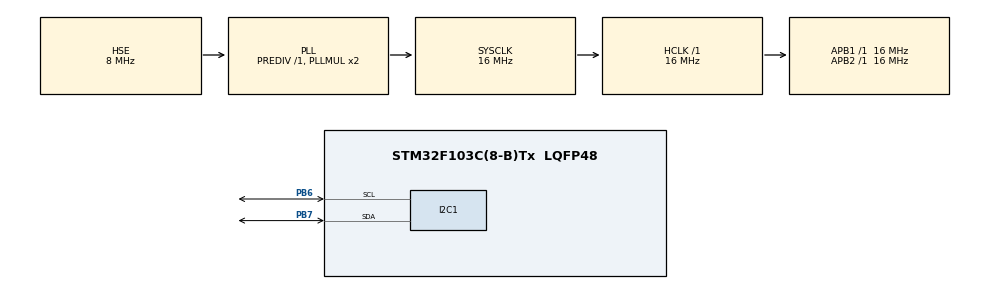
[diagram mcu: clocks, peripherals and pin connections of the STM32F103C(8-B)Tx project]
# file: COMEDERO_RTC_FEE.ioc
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Mcu.Family=STM32F1
Mcu.Name=STM32F103C(8-B)Tx
Mcu.Package=LQFP48
NVIC.PriorityGroup=NVIC_PRIORITYGROUP_4
PA13.Mode=Serial_Wire
PA13.Signal=SYS_JTMS-SWDIO
PA14.Mode=Serial_Wire
PA14.Signal=SYS_JTCK-SWCLK
PB6.Mode=I2C
PB6.Signal=I2C1_SCL
PB7.Mode=I2C
PB7.Signal=I2C1_SDA
PD0-OSC_IN.Mode=HSE-External-Oscillator
PD0-OSC_IN.Signal=RCC_OSC_IN
PD1-OSC_OUT.Mode=HSE-External-Oscillator
PD1-OSC_OUT.Signal=RCC_OSC_OUT
ProjectManager.HeapSize=0x200
ProjectManager.StackSize=0x400
ProjectManager.TargetToolchain=STM32CubeIDE
RCC.AHBFreq_Value=16000000
RCC.APB1Freq_Value=16000000
RCC.APB1TimFreq_Value=16000000
RCC.APB2Freq_Value=16000000
RCC.APB2TimFreq_Value=16000000
RCC.HCLKFreq_Value=16000000
RCC.PLLSourceVirtual=RCC_PLLSOURCE_HSE
RCC.SYSCLKFreq_VALUE=16000000
RCC.SYSCLKSource=RCC_SYSCLKSOURCE_PLLCLK
RCC.USBFreq_Value=16000000
RTC.Hours=16
RTC.Minutes=10
TIM2.Prescaler=15
VP_RTC_VS_RTC_Activate.Mode=RTC_Enabled
VP_RTC_VS_RTC_Calendar.Mode=RTC_Calendar
VP_TIM2_VS_ClockSourceINT.Mode=Internal
board=custom

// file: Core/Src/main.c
/* USER CODE BEGIN Header */
/**
  ******************************************************************************
  * @file           : main.c
  * @brief          : Main program body
  ******************************************************************************
  * @attention
  *
  * Copyright (c) 2025 STMicroelectronics.
  * All rights reserved.
  *
  * This software is licensed under terms that can be found in the LICENSE file
  * in the root directory of this software component.
  * If no LICENSE file comes with this software, it is provided AS-IS.
  *
  ******************************************************************************
  */
/* USER CODE END Header */
#include "main.h"

/* USER CODE BEGIN Includes */
#include "I2C_LCD.h"
#include "FEE.h"
/* USER CODE END Includes */

/* USER CODE BEGIN PD */

#define MyI2C_LCD I2C_LCD_1

/* USER CODE END PD */

I2C_HandleTypeDef hi2c1;

RTC_HandleTypeDef hrtc;

TIM_HandleTypeDef htim2;

/* USER CODE BEGIN PV */
RTC_TimeTypeDef gTime;
/* USER CODE END PV */

void SystemClock_Config(void);
static void MX_GPIO_Init(void);
static void MX_TIM2_Init(void);
static void MX_I2C1_Init(void);
static void MX_RTC_Init(void);

int main(void)
{

  /* USER CODE BEGIN 1 */

	uint16_t i = 0;
  /* USER CODE END 1 */

  /* MCU Configuration--------------------------------------------------------*/

  /* Reset of all peripherals, Initializes the Flash interface and the Systick. */
  HAL_Init();

  /* Configure the system clock */
  SystemClock_Config();

  /* Initialize all configured peripherals */
  MX_GPIO_Init();
  MX_TIM2_Init();
  MX_I2C1_Init();
  MX_RTC_Init();
  /* USER CODE BEGIN 2 */
  I2C_LCD_Init(MyI2C_LCD);
  I2C_LCD_SetCursor(MyI2C_LCD, 0, 0);
  I2C_LCD_WriteString(MyI2C_LCD, "Hora actual: ");
  I2C_LCD_SetCursor(MyI2C_LCD, 0, 1);

  FEE_ReadData(FEE_START_ADDRESS, &gTime, sizeof(RTC_TimeTypeDef));
  HAL_RTC_SetTime(&hrtc, &gTime, RTC_FORMAT_BIN);
  /* USER CODE END 2 */

  /* Infinite loop */
  /* USER CODE BEGIN WHILE */
  while (1)
  {
	  HAL_RTC_GetTime(&hrtc, &gTime, RTC_FORMAT_BIN);
	  I2C_LCD_WriteInt32(MyI2C_LCD, (int32_t)gTime.Hours);
	  I2C_LCD_WriteChar(MyI2C_LCD, ':');
	  I2C_LCD_WriteInt32(MyI2C_LCD, (int32_t)gTime.Minutes);
	  I2C_LCD_WriteChar(MyI2C_LCD, ':');
	  I2C_LCD_WriteInt32(MyI2C_LCD, (int32_t)gTime.Seconds);
	  I2C_LCD_SetCursor(MyI2C_LCD, 0, 1);
	  HAL_Delay(1000);
	  I2C_LCD_WriteString(MyI2C_LCD, "                ");
	  I2C_LCD_SetCursor(MyI2C_LCD, 0, 1);
    /* USER CODE END WHILE */

    /* USER CODE BEGIN 3 */
	  i++;
	  if(i == 300)
	  {
		  FEE_WriteData(FEE_START_ADDRESS, &gTime, sizeof(RTC_TimeTypeDef));
	  }
  }
  /* USER CODE END 3 */
}

void SystemClock_Config(void)
{
  RCC_OscInitTypeDef RCC_OscInitStruct = {0};
  RCC_ClkInitTypeDef RCC_ClkInitStruct = {0};
  RCC_PeriphCLKInitTypeDef PeriphClkInit = {0};

  /** Initializes the RCC Oscillators according to the specified parameters
  * in the RCC_OscInitTypeDef structure.
  */
  RCC_OscInitStruct.OscillatorType = RCC_OSCILLATORTYPE_LSI|RCC_OSCILLATORTYPE_HSE;
  RCC_OscInitStruct.HSEState = RCC_HSE_ON;
  RCC_OscInitStruct.HSEPredivValue = RCC_HSE_PREDIV_DIV1;
  RCC_OscInitStruct.HSIState = RCC_HSI_ON;
  RCC_OscInitStruct.LSIState = RCC_LSI_ON;
  RCC_OscInitStruct.PLL.PLLState = RCC_PLL_ON;
  RCC_OscInitStruct.PLL.PLLSource = RCC_PLLSOURCE_HSE;
  RCC_OscInitStruct.PLL.PLLMUL = RCC_PLL_MUL2;
  if (HAL_RCC_OscConfig(&RCC_OscInitStruct) != HAL_OK)
  {
    Error_Handler();
  }

  /** Initializes the CPU, AHB and APB buses clocks
  */
  RCC_ClkInitStruct.ClockType = RCC_CLOCKTYPE_HCLK|RCC_CLOCKTYPE_SYSCLK
                              |RCC_CLOCKTYPE_PCLK1|RCC_CLOCKTYPE_PCLK2;
  RCC_ClkInitStruct.SYSCLKSource = RCC_SYSCLKSOURCE_PLLCLK;
  RCC_ClkInitStruct.AHBCLKDivider = RCC_SYSCLK_DIV1;
  RCC_ClkInitStruct.APB1CLKDivider = RCC_HCLK_DIV1;
  RCC_ClkInitStruct.APB2CLKDivider = RCC_HCLK_DIV1;

  if (HAL_RCC_ClockConfig(&RCC_ClkInitStruct, FLASH_LATENCY_0) != HAL_OK)
  {
    Error_Handler();
  }
  PeriphClkInit.PeriphClockSelection = RCC_PERIPHCLK_RTC;
  PeriphClkInit.RTCClockSelection = RCC_RTCCLKSOURCE_LSI;
  if (HAL_RCCEx_PeriphCLKConfig(&PeriphClkInit) != HAL_OK)
  {
    Error_Handler();
  }
}

static void MX_I2C1_Init(void)
{

  hi2c1.Instance = I2C1;
  hi2c1.Init.ClockSpeed = 100000;
  hi2c1.Init.DutyCycle = I2C_DUTYCYCLE_2;
  hi2c1.Init.OwnAddress1 = 0;
  hi2c1.Init.AddressingMode = I2C_ADDRESSINGMODE_7BIT;
  hi2c1.Init.DualAddressMode = I2C_DUALADDRESS_DISABLE;
  hi2c1.Init.OwnAddress2 = 0;
  hi2c1.Init.GeneralCallMode = I2C_GENERALCALL_DISABLE;
  hi2c1.Init.NoStretchMode = I2C_NOSTRETCH_DISABLE;
  if (HAL_I2C_Init(&hi2c1) != HAL_OK)
  {
    Error_Handler();
  }

}

static void MX_RTC_Init(void)
{

  RTC_TimeTypeDef sTime = {0};
  RTC_DateTypeDef DateToUpdate = {0};

  /** Initialize RTC Only
  */
  hrtc.Instance = RTC;
  hrtc.Init.AsynchPrediv = RTC_AUTO_1_SECOND;
  hrtc.Init.OutPut = RTC_OUTPUTSOURCE_ALARM;
  if (HAL_RTC_Init(&hrtc) != HAL_OK)
  {
    Error_Handler();
  }

  /** Initialize RTC and set the Time and Date
  */
  sTime.Hours = 0x16;
  sTime.Minutes = 0x10;
  sTime.Seconds = 0x0;

  if (HAL_RTC_SetTime(&hrtc, &sTime, RTC_FORMAT_BCD) != HAL_OK)
  {
    Error_Handler();
  }
  DateToUpdate.WeekDay = RTC_WEEKDAY_MONDAY;
  DateToUpdate.Month = RTC_MONTH_JANUARY;
  DateToUpdate.Date = 0x1;
  DateToUpdate.Year = 0x0;

  if (HAL_RTC_SetDate(&hrtc, &DateToUpdate, RTC_FORMAT_BCD) != HAL_OK)
  {
    Error_Handler();
  }

}

static void MX_TIM2_Init(void)
{

  TIM_ClockConfigTypeDef sClockSourceConfig = {0};
  TIM_MasterConfigTypeDef sMasterConfig = {0};

  htim2.Instance = TIM2;
  htim2.Init.Prescaler = 15;
  htim2.Init.CounterMode = TIM_COUNTERMODE_UP;
  htim2.Init.Period = 65535;
  htim2.Init.ClockDivision = TIM_CLOCKDIVISION_DIV1;
  htim2.Init.AutoReloadPreload = TIM_AUTORELOAD_PRELOAD_DISABLE;
  if (HAL_TIM_Base_Init(&htim2) != HAL_OK)
  {
    Error_Handler();
  }
  sClockSourceConfig.ClockSource = TIM_CLOCKSOURCE_INTERNAL;
  if (HAL_TIM_ConfigClockSource(&htim2, &sClockSourceConfig) != HAL_OK)
  {
    Error_Handler();
  }
  sMasterConfig.MasterOutputTrigger = TIM_TRGO_RESET;
  sMasterConfig.MasterSlaveMode = TIM_MASTERSLAVEMODE_DISABLE;
  if (HAL_TIMEx_MasterConfigSynchronization(&htim2, &sMasterConfig) != HAL_OK)
  {
    Error_Handler();
  }

}

static void MX_GPIO_Init(void)
{

  /* GPIO Ports Clock Enable */
  __HAL_RCC_GPIOD_CLK_ENABLE();
  __HAL_RCC_GPIOA_CLK_ENABLE();
  __HAL_RCC_GPIOB_CLK_ENABLE();

}

void Error_Handler(void)
{
  __disable_irq();
  while (1)
  {
  }
}
